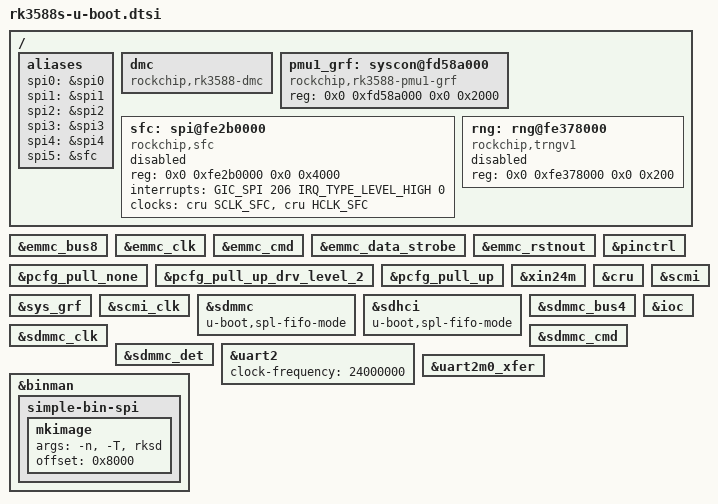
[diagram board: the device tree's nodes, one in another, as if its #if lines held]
// SPDX-License-Identifier: (GPL-2.0+ OR MIT)
/*
 * Copyright (c) 2022 Edgeble AI Technologies Pvt. Ltd.
 */

#include "rockchip-u-boot.dtsi"
#include <dt-bindings/phy/phy.h>

/ {
	aliases {
		spi0 = &spi0;
		spi1 = &spi1;
		spi2 = &spi2;
		spi3 = &spi3;
		spi4 = &spi4;
		spi5 = &sfc;
	};

	dmc {
		compatible = "rockchip,rk3588-dmc";
		bootph-all;
		status = "okay";
	};

	pmu1_grf: syscon@fd58a000 {
		bootph-all;
		compatible = "rockchip,rk3588-pmu1-grf", "syscon";
		reg = <0x0 0xfd58a000 0x0 0x2000>;
	};
	sfc: spi@fe2b0000 {
		compatible = "rockchip,sfc";
		reg = <0x0 0xfe2b0000 0x0 0x4000>;
		interrupts = <GIC_SPI 206 IRQ_TYPE_LEVEL_HIGH 0>;
		clocks = <&cru SCLK_SFC>, <&cru HCLK_SFC>;
		clock-names = "clk_sfc", "hclk_sfc";
		status = "disabled";
	};

	rng: rng@fe378000 {
		compatible = "rockchip,trngv1";
		reg = <0x0 0xfe378000 0x0 0x200>;
		status = "disabled";
	};
};

&emmc_bus8 {
	bootph-all;
};

&emmc_clk {
	bootph-all;
};

&emmc_cmd {
	bootph-all;
};

&emmc_data_strobe {
	bootph-all;
};

&emmc_rstnout {
	bootph-all;
};

&pinctrl {
	bootph-all;
};

&pcfg_pull_none {
	bootph-all;
};

&pcfg_pull_up_drv_level_2 {
	bootph-all;
};

&pcfg_pull_up {
	bootph-all;
};

&xin24m {
	bootph-all;
	status = "okay";
};

&cru {
	bootph-pre-ram;
	status = "okay";
};

&sys_grf {
	bootph-pre-ram;
	status = "okay";
};

&scmi {
	bootph-pre-ram;
};

&scmi_clk {
	bootph-pre-ram;
};

&sdmmc {
	bootph-pre-ram;
	u-boot,spl-fifo-mode;
};

&sdhci {
	bootph-pre-ram;
	u-boot,spl-fifo-mode;
};

&sdmmc_bus4 {
	bootph-all;
};

&sdmmc_clk {
	bootph-all;
};

&sdmmc_cmd {
	bootph-all;
};

&sdmmc_det {
	bootph-all;
};

&uart2 {
	clock-frequency = <24000000>;
	bootph-pre-ram;
	status = "okay";
};

&uart2m0_xfer {
	bootph-all;
};

&ioc {
	bootph-pre-ram;
};

#ifdef CONFIG_ROCKCHIP_SPI_IMAGE
&binman {
	simple-bin-spi {
		mkimage {
			args = "-n", CONFIG_SYS_SOC, "-T", "rksd";
			offset = <0x8000>;
		};
	};
};
#endif
